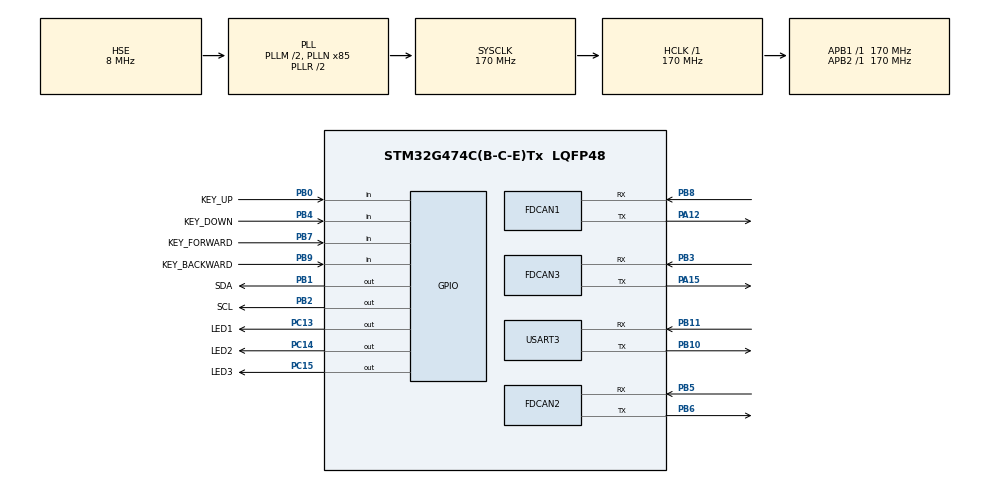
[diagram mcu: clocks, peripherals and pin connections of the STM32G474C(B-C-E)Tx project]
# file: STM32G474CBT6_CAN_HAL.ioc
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FDCAN1.CalculateBaudRateNominal=3541666
FDCAN1.CalculateTimeBitNominal=282
FDCAN1.CalculateTimeQuantumNominal=94.11764705882354
FDCAN2.CalculateBaudRateNominal=1000000
FDCAN2.CalculateTimeBitNominal=1000
FDCAN2.CalculateTimeQuantumNominal=100.0
FDCAN2.Mode=FDCAN_MODE_NORMAL
FDCAN2.NominalPrescaler=17
FDCAN2.NominalTimeSeg1=5
FDCAN2.NominalTimeSeg2=4
FDCAN2.StdFiltersNbr=1
FDCAN3.CalculateBaudRateNominal=1000000
FDCAN3.CalculateTimeBitNominal=1000
FDCAN3.CalculateTimeQuantumNominal=100.0
FDCAN3.Mode=FDCAN_MODE_NORMAL
FDCAN3.NominalPrescaler=17
FDCAN3.NominalTimeSeg1=5
FDCAN3.NominalTimeSeg2=4
FDCAN3.StdFiltersNbr=1
Mcu.Family=STM32G4
Mcu.Name=STM32G474C(B-C-E)Tx
Mcu.Package=LQFP48
NVIC.PriorityGroup=NVIC_PRIORITYGROUP_2
NVIC.TIM3_IRQn=true\:2\:2\:true\:false\:true\:true\:true\:true
PA12.Mode=FDCAN_Activate
PA12.Signal=FDCAN1_TX
PA13.Mode=Serial_Wire
PA13.Signal=SYS_JTMS-SWDIO
PA14.Mode=Serial_Wire
PA14.Signal=SYS_JTCK-SWCLK
PA15.GPIO_PuPd=GPIO_NOPULL
PA15.GPIO_Speed=GPIO_SPEED_FREQ_VERY_HIGH
PA15.Mode=FDCAN_Activate
PA15.Signal=FDCAN3_TX
PB0.GPIO_Label=KEY_UP
PB0.GPIO_PuPd=GPIO_PULLUP
PB0.Signal=GPIO_Input
PB1.GPIO_Label=SDA
PB1.GPIO_PuPd=GPIO_PULLUP
PB1.GPIO_Speed=GPIO_SPEED_FREQ_VERY_HIGH
PB1.Signal=GPIO_Output
PB10.Mode=Asynchronous
PB10.Signal=USART3_TX
PB11.Mode=Asynchronous
PB11.Signal=USART3_RX
PB2.GPIO_Label=SCL
PB2.GPIO_PuPd=GPIO_PULLUP
PB2.GPIO_Speed=GPIO_SPEED_FREQ_VERY_HIGH
PB2.Signal=GPIO_Output
PB3.GPIO_PuPd=GPIO_NOPULL
PB3.GPIO_Speed=GPIO_SPEED_FREQ_VERY_HIGH
PB3.Mode=FDCAN_Activate
PB3.Signal=FDCAN3_RX
PB4.GPIO_Label=KEY_DOWN
PB4.GPIO_PuPd=GPIO_PULLUP
PB4.Signal=GPIO_Input
PB5.GPIO_PuPd=GPIO_NOPULL
PB5.GPIO_Speed=GPIO_SPEED_FREQ_VERY_HIGH
PB5.Mode=FDCAN_Activate
PB5.Signal=FDCAN2_RX
PB6.GPIO_FM6=SYSCFG_FASTMODEPLUS_PB6
PB6.GPIO_PuPd=GPIO_NOPULL
PB6.GPIO_Speed=GPIO_SPEED_FREQ_VERY_HIGH
PB6.Mode=FDCAN_Activate
PB6.Signal=FDCAN2_TX
PB7.GPIO_Label=KEY_FORWARD
PB7.GPIO_PuPd=GPIO_PULLUP
PB7.Signal=GPIO_Input
PB8-BOOT0.Mode=FDCAN_Activate
PB8-BOOT0.Signal=FDCAN1_RX
PB9.GPIO_Label=KEY_BACKWARD
PB9.GPIO_PuPd=GPIO_PULLUP
PB9.Signal=GPIO_Input
PC13.GPIO_Label=LED1
PC13.PinState=GPIO_PIN_SET
PC13.Signal=GPIO_Output
PC14-OSC32_IN.GPIO_Label=LED2
PC14-OSC32_IN.PinState=GPIO_PIN_SET
PC14-OSC32_IN.Signal=GPIO_Output
PC15-OSC32_OUT.GPIO_Label=LED3
PC15-OSC32_OUT.PinState=GPIO_PIN_SET
PC15-OSC32_OUT.Signal=GPIO_Output
PF0-OSC_IN.Mode=HSE-External-Oscillator
PF0-OSC_IN.Signal=RCC_OSC_IN
PF1-OSC_OUT.Mode=HSE-External-Oscillator
PF1-OSC_OUT.Signal=RCC_OSC_OUT
ProjectManager.HeapSize=0x200
ProjectManager.StackSize=0x400
ProjectManager.TargetToolchain=MDK-ARM V5.32
RCC.ADC12Freq_Value=170000000
RCC.ADC345Freq_Value=170000000
RCC.AHBFreq_Value=170000000
RCC.APB1Freq_Value=170000000
RCC.APB1TimFreq_Value=170000000
RCC.APB2Freq_Value=170000000
RCC.APB2TimFreq_Value=170000000
RCC.CortexFreq_Value=170000000
RCC.EXTERNAL_CLOCK_VALUE=12288000
RCC.HCLKFreq_Value=170000000
RCC.HSE_VALUE=8000000
RCC.HSI48_VALUE=48000000
RCC.HSI_VALUE=16000000
RCC.LSE_VALUE=32768
RCC.PLLM=RCC_PLLM_DIV2
RCC.PLLN=85
RCC.PLLSourceVirtual=RCC_PLLSOURCE_HSE
RCC.SYSCLKFreq_VALUE=170000000
RCC.SYSCLKSource=RCC_SYSCLKSOURCE_PLLCLK
RCC.USBFreq_Value=170000000
RCC.VCOOutputFreq_Value=340000000
TIM3.TIM_MasterOutputTrigger=TIM_TRGO_UPDATE
USART3.VirtualMode-Asynchronous=VM_ASYNC
VP_SYS_VS_DBSignals.Mode=DisableDeadBatterySignals
VP_TIM3_VS_ClockSourceINT.Mode=Internal
board=custom

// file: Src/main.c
/* USER CODE BEGIN Header */
/**
  ******************************************************************************
  * @file           : main.c
  * @brief          : Main program body
  ******************************************************************************
  * @attention
  *
  * Copyright (c) 2025 STMicroelectronics.
  * All rights reserved.
  *
  * This software is licensed under terms that can be found in the LICENSE file
  * in the root directory of this software component.
  * If no LICENSE file comes with this software, it is provided AS-IS.
  *
  ******************************************************************************
  */
/* USER CODE END Header */
#include "main.h"
#include "fdcan.h"
#include "tim.h"
#include "usart.h"
#include "gpio.h"

/* USER CODE BEGIN Includes */
#include "System/System.h"
/* USER CODE END Includes */

void SystemClock_Config(void);

int main(void)
{

  /* MCU Configuration--------------------------------------------------------*/

  /* Reset of all peripherals, Initializes the Flash interface and the Systick. */
  HAL_Init();

  /* Configure the system clock */
  SystemClock_Config();

  /* Initialize all configured peripherals */
  MX_GPIO_Init();
  MX_FDCAN1_Init();
  MX_FDCAN2_Init();
  MX_FDCAN3_Init();
  MX_USART3_UART_Init();
  MX_TIM3_Init();
  /* USER CODE BEGIN 2 */
    System_Init();
  /* USER CODE END 2 */

  /* Infinite loop */
  /* USER CODE BEGIN WHILE */
  while (1)
  {
      System_Run();
    /* USER CODE END WHILE */

  }
}

void SystemClock_Config(void)
{
  RCC_OscInitTypeDef RCC_OscInitStruct = {0};
  RCC_ClkInitTypeDef RCC_ClkInitStruct = {0};

  /** Configure the main internal regulator output voltage
  */
  HAL_PWREx_ControlVoltageScaling(PWR_REGULATOR_VOLTAGE_SCALE1_BOOST);

  /** Initializes the RCC Oscillators according to the specified parameters
  * in the RCC_OscInitTypeDef structure.
  */
  RCC_OscInitStruct.OscillatorType = RCC_OSCILLATORTYPE_HSE;
  RCC_OscInitStruct.HSEState = RCC_HSE_ON;
  RCC_OscInitStruct.PLL.PLLState = RCC_PLL_ON;
  RCC_OscInitStruct.PLL.PLLSource = RCC_PLLSOURCE_HSE;
  RCC_OscInitStruct.PLL.PLLM = RCC_PLLM_DIV2;
  RCC_OscInitStruct.PLL.PLLN = 85;
  RCC_OscInitStruct.PLL.PLLP = RCC_PLLP_DIV2;
  RCC_OscInitStruct.PLL.PLLQ = RCC_PLLQ_DIV2;
  RCC_OscInitStruct.PLL.PLLR = RCC_PLLR_DIV2;
  if (HAL_RCC_OscConfig(&RCC_OscInitStruct) != HAL_OK)
  {
    Error_Handler();
  }

  /** Initializes the CPU, AHB and APB buses clocks
  */
  RCC_ClkInitStruct.ClockType = RCC_CLOCKTYPE_HCLK|RCC_CLOCKTYPE_SYSCLK
                              |RCC_CLOCKTYPE_PCLK1|RCC_CLOCKTYPE_PCLK2;
  RCC_ClkInitStruct.SYSCLKSource = RCC_SYSCLKSOURCE_PLLCLK;
  RCC_ClkInitStruct.AHBCLKDivider = RCC_SYSCLK_DIV1;
  RCC_ClkInitStruct.APB1CLKDivider = RCC_HCLK_DIV1;
  RCC_ClkInitStruct.APB2CLKDivider = RCC_HCLK_DIV1;

  if (HAL_RCC_ClockConfig(&RCC_ClkInitStruct, FLASH_LATENCY_4) != HAL_OK)
  {
    Error_Handler();
  }
}

void Error_Handler(void)
{
  __disable_irq();
  while (1)
  {
  }
}
